# STM32H747_CM7 register map
File version: 2.4
CPU: CM7 r0p1, little endian, MPU, FPU, 4 interrupt priority bits
Registers are 32-bit, read-write, reset 0x0 unless marked. A register's access mark holds for its fields unless they carry their own. Offsets are from the block's base; [hi:lo] are bit positions; {n}, {i} and the like mark numbered series; 'fields as' and 'values as' point back to an identical list.

## MDIOS — Management data input/output slave
Base 0x40009400
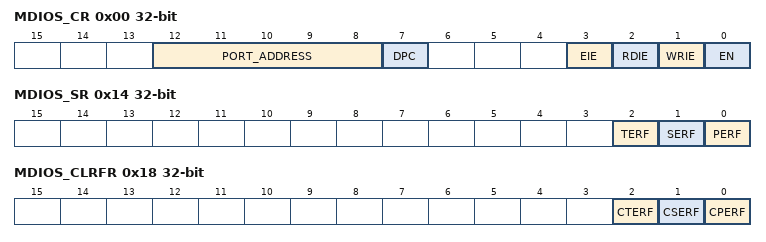
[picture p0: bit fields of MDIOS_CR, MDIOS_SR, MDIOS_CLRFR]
0x00 MDIOS_CR — MDIOS configuration register
  [12:8] PORT_ADDRESS — Slaves's address
  [7] DPC — Disable Preamble Check
  [3] EIE — Error interrupt enable
  [2] RDIE — Register Read Interrupt Enable
  [1] WRIE — Register write interrupt enable
  [0] EN — Peripheral enable
0x04 MDIOS_WRFR ro — MDIOS write flag register
  [31:0] WRF — Write flags for MDIO registers 0 to 31
0x08 MDIOS_CWRFR — MDIOS clear write flag register
  [31:0] CWRF — Clear the write flag
0x0C MDIOS_RDFR ro — MDIOS read flag register
  [31:0] RDF — Read flags for MDIO registers 0 to 31
0x10 MDIOS_CRDFR — MDIOS clear read flag register
  [31:0] CRDF — Clear the read flag
0x14 MDIOS_SR ro — MDIOS status register
  [2] TERF — Turnaround error flag
  [1] SERF — Start error flag
  [0] PERF — Preamble error flag
0x18 MDIOS_CLRFR — MDIOS clear flag register
  [2] CTERF — Clear the turnaround error flag
  [1] CSERF — Clear the start error flag
  [0] CPERF — Clear the preamble error flag
{0x1C+4i} MDIOS_DINR{i} ro (i=0..31) — MDIOS input data register {i}
  [15:0] DIN{i} — Input data received from MDIO Master during write frames
{0x9C+4i} MDIOS_DOUTR{i} (i=0..31) — MDIOS output data register {i}
  [15:0] DOUT{i} — Output data sent to MDIO Master during read frames

## OPAMP — Operational amplifiers
Base 0x40009000
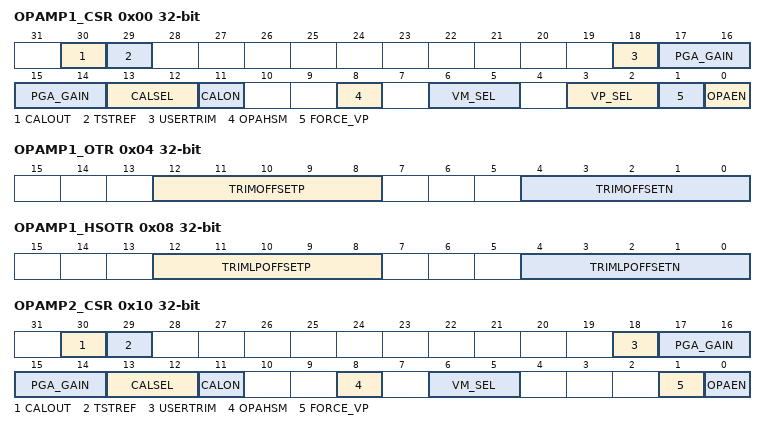
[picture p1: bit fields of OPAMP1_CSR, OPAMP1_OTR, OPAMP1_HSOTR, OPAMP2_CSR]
0x00 OPAMP1_CSR — OPAMP1 control/status register
  [30] CALOUT — Operational amplifier calibration output
  [29] TSTREF — OPAMP calibration reference voltage output control (reserved for test)
  [18] USERTRIM — User trimming enable
  [17:14] PGA_GAIN — allows to switch from AOP offset trimmed values to AOP offset
  [13:12] CALSEL — Calibration selection
  [11] CALON — Calibration mode enabled
  [8] OPAHSM — Operational amplifier high-speed mode
  [6:5] VM_SEL — Inverting input selection
  [3:2] VP_SEL — Operational amplifier PGA mode
  [1] FORCE_VP — Force internal reference on VP (reserved for test
  [0] OPAEN — Operational amplifier Enable
0x04 OPAMP1_OTR — OPAMP1 offset trimming register in normal mode
  [12:8] TRIMOFFSETP — Trim for PMOS differential pairs
  [4:0] TRIMOFFSETN — Trim for NMOS differential pairs
0x08 OPAMP1_HSOTR — OPAMP1 offset trimming register in low-power mode
  [12:8] TRIMLPOFFSETP — Trim for PMOS differential pairs
  [4:0] TRIMLPOFFSETN — Trim for NMOS differential pairs
0x10 OPAMP2_CSR — OPAMP2 control/status register
  [30] CALOUT — Operational amplifier calibration output
  [29] TSTREF — OPAMP calibration reference voltage output control (reserved for test)
  [18] USERTRIM — User trimming enable
  [17:14] PGA_GAIN — Operational amplifier Programmable amplifier gain value
  [13:12] CALSEL — Calibration selection
  [11] CALON — Calibration mode enabled
  [8] OPAHSM — Operational amplifier high-speed mode
  [6:5] VM_SEL — Inverting input selection
  [1] FORCE_VP — Force internal reference on VP (reserved for test)
  [0] OPAEN — Operational amplifier Enable
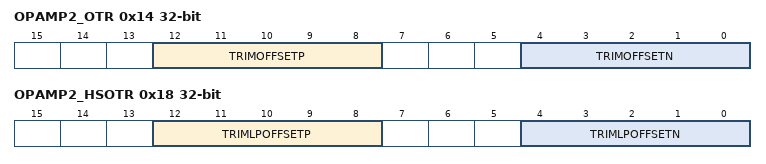
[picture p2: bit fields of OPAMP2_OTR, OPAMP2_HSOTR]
0x14 OPAMP2_OTR — OPAMP2 offset trimming register in normal mode
  fields as OPAMP1_OTR
0x18 OPAMP2_HSOTR — OPAMP2 offset trimming register in low-power mode
  fields as OPAMP1_HSOTR

## SWPMI — Single Wire Protocol Master Interface
Base 0x40008800
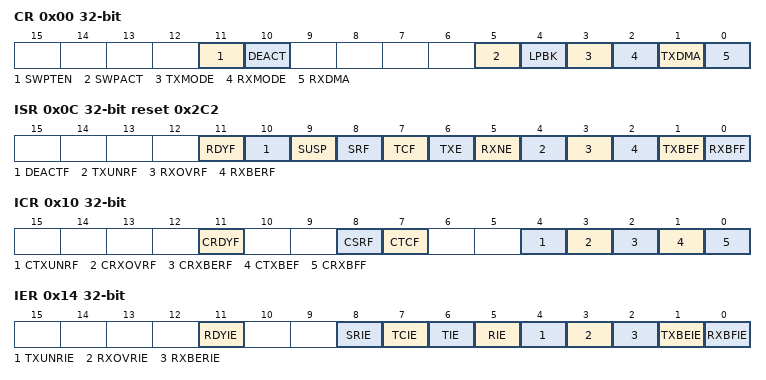
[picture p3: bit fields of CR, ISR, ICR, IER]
0x00 CR — SWPMI Configuration/Control register
  [11] SWPTEN — Single wire protocol master transceiver enable
  [10] DEACT — Single wire protocol master interface deactivate
  [5] SWPACT — Single wire protocol master interface activate
  [4] LPBK — Loopback mode enable
  [3] TXMODE — Transmission buffering mode
  [2] RXMODE — Reception buffering mode
  [1] TXDMA — Transmission DMA enable
  [0] RXDMA — Reception DMA enable
0x04 BRR reset 0x1 — SWPMI Bitrate register
  [7:0] BR — Bitrate prescaler
0x0C ISR ro reset 0x2C2 — SWPMI Interrupt and Status register
  [11] RDYF — transceiver ready flag
  [10] DEACTF — DEACTIVATED flag
  [9] SUSP — SUSPEND flag
  [8] SRF — Slave resume flag
  [7] TCF — Transfer complete flag
  [6] TXE — Transmit data register empty
  [5] RXNE — Receive data register not empty
  [4] TXUNRF — Transmit underrun error flag
  [3] RXOVRF — Receive overrun error flag
  [2] RXBERF — Receive CRC error flag
  [1] TXBEF — Transmit buffer empty flag
  [0] RXBFF — Receive buffer full flag
0x10 ICR wo — SWPMI Interrupt Flag Clear register
  [11] CRDYF — Clear transceiver ready flag
  [8] CSRF — Clear slave resume flag
  [7] CTCF — Clear transfer complete flag
  [4] CTXUNRF — Clear transmit underrun error flag
  [3] CRXOVRF — Clear receive overrun error flag
  [2] CRXBERF — Clear receive CRC error flag
  [1] CTXBEF — Clear transmit buffer empty flag
  [0] CRXBFF — Clear receive buffer full flag
0x14 IER — SWPMI Interrupt Enable register
  [11] RDYIE — Transceiver ready interrupt enable
  [8] SRIE — Slave resume interrupt enable
  [7] TCIE — Transmit complete interrupt enable
  [6] TIE — Transmit interrupt enable
  [5] RIE — Receive interrupt enable
  [4] TXUNRIE — Transmit underrun error interrupt enable
  [3] RXOVRIE — Receive overrun error interrupt enable
  [2] RXBERIE — Receive CRC error interrupt enable
  [1] TXBEIE — Transmit buffer empty interrupt enable
  [0] RXBFIE — Receive buffer full interrupt enable
0x18 RFL ro — SWPMI Receive Frame Length register
  [4:0] RFL — Receive frame length
0x1C TDR wo — SWPMI Transmit data register
  [31:0] TD — Transmit data
0x20 RDR ro — SWPMI Receive data register
  [31:0] RD — received data
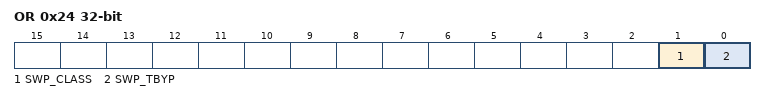
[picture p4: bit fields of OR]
0x24 OR — SWPMI Option register
  [1] SWP_CLASS — SWP class selection
  [0] SWP_TBYP — SWP transceiver bypass

## Notices in the file
Copyright (c) 2025 STMicroelectronics.
SPDX-License-Identifier: Apache-2.0
Licensed under the Apache License, Version 2.0 (the "License");
you may not use this file except in compliance with the License.
You may obtain a copy of the License at
http://www.apache.org/licenses/LICENSE-2.0
Unless required by applicable law or agreed to in writing, software
distributed under the License is distributed on an "AS IS" BASIS,
WITHOUT WARRANTIES OR CONDITIONS OF ANY KIND, either express or implied.
See the License for the specific language governing permissions and
limitations under the License.
